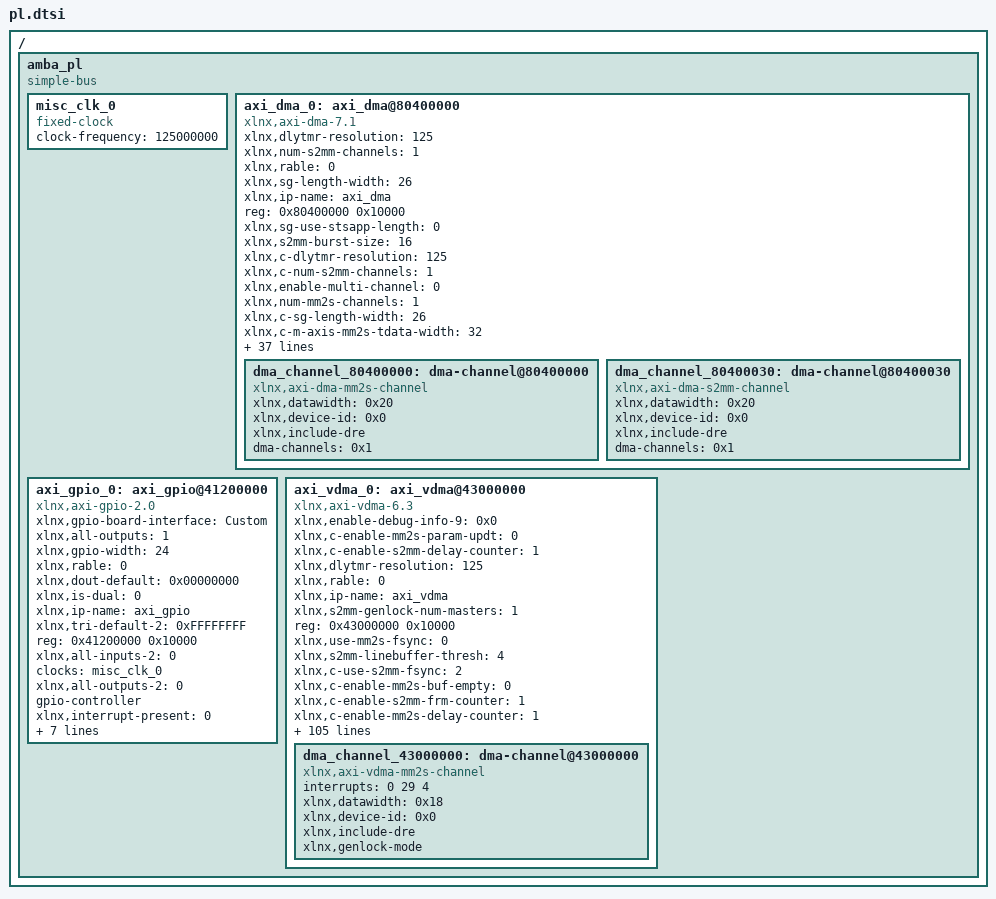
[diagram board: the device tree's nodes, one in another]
/ {
	amba_pl: amba_pl {
		ranges;
		compatible = "simple-bus";
		#address-cells = <1>;
		#size-cells = <1>;
		misc_clk_0: misc_clk_0 {
			compatible = "fixed-clock";
			clock-frequency = <125000000>;
			#clock-cells = <0>;
		};
		axi_dma_0: axi_dma@80400000 {
			xlnx,dlytmr-resolution = <125>;
			xlnx,num-s2mm-channels = <1>;
			xlnx,rable = <0>;
			xlnx,sg-length-width = <26>;
			xlnx,ip-name = "axi_dma";
			reg = <0x80400000 0x10000>;
			xlnx,sg-use-stsapp-length = <0>;
			xlnx,s2mm-burst-size = <16>;
			xlnx,c-dlytmr-resolution = <125>;
			xlnx,c-num-s2mm-channels = <1>;
			xlnx,enable-multi-channel = <0>;
			xlnx,num-mm2s-channels = <1>;
			xlnx,c-sg-length-width = <26>;
			compatible = "xlnx,axi-dma-7.1" , "xlnx,axi-dma-1.00.a";
			xlnx,c-m-axis-mm2s-tdata-width = <32>;
			xlnx,c-sg-use-stsapp-length = <0>;
			xlnx,c-s2mm-burst-size = <16>;
			xlnx,mm2s-burst-size = <16>;
			xlnx,c-enable-multi-channel = <0>;
			xlnx,c-num-mm2s-channels = <1>;
			xlnx,include-s2mm-dre = <1>;
			xlnx,c-mm2s-burst-size = <16>;
			status = "okay";
			xlnx,c-include-s2mm-dre = <1>;
			xlnx,include-mm2s-dre = <1>;
			xlnx,name = "axi_dma_0";
			xlnx,c-include-sg = <0>;
			xlnx,c-m-axi-s2mm-data-width = <32>;
			xlnx,include-s2mm-sf = <1>;
			xlnx,c-include-mm2s-dre = <1>;
			xlnx,include-s2mm = <1>;
			clocks = <&clkc 15>, <&clkc 15>, <&clkc 15>;
			xlnx,addrwidth = <0x20>;
			xlnx,c-m-axi-mm2s-data-width = <32>;
			xlnx,edk-iptype = "PERIPHERAL";
			xlnx,c-include-s2mm-sf = <1>;
			xlnx,include-mm2s-sf = <1>;
			clock-names = "m_axi_mm2s_aclk" , "m_axi_s2mm_aclk" , "s_axi_lite_aclk";
			xlnx,c-include-s2mm = <1>;
			xlnx,c-addr-width = <32>;
			xlnx,c-single-interface = <0>;
			xlnx,include-mm2s = <1>;
			xlnx,c-s-axis-s2mm-tdata-width = <32>;
			xlnx,s2mm-data-width = <0x20>;
			xlnx,c-include-mm2s-sf = <1>;
			xlnx,prmry-is-aclk-async = <0>;
			xlnx,c-include-mm2s = <1>;
			xlnx,increase-throughput = <0>;
			xlnx,micro-dma = <0>;
			xlnx,mm2s-data-width = <0x20>;
			xlnx,c-prmry-is-aclk-async = <0>;
			xlnx,c-sg-include-stscntrl-strm = <0>;
			xlnx,c-increase-throughput = <0>;
			xlnx,c-micro-dma = <0>;
			dma_channel_80400000: dma-channel@80400000 {
				xlnx,datawidth = <0x20>;
				xlnx,device-id = <0x0>;
				compatible = "xlnx,axi-dma-mm2s-channel";
				xlnx,include-dre;
				dma-channels = <0x1>;
			};
			dma_channel_80400030: dma-channel@80400030 {
				xlnx,datawidth = <0x20>;
				xlnx,device-id = <0x0>;
				compatible = "xlnx,axi-dma-s2mm-channel";
				xlnx,include-dre;
				dma-channels = <0x1>;
			};
		};
		axi_gpio_0: axi_gpio@41200000 {
			xlnx,gpio-board-interface = "Custom";
			compatible = "xlnx,axi-gpio-2.0" , "xlnx,xps-gpio-1.00.a";
			xlnx,all-outputs = <1>;
			#gpio-cells = <2>;
			xlnx,gpio-width = <24>;
			xlnx,rable = <0>;
			xlnx,dout-default = <0x00000000>;
			xlnx,is-dual = <0>;
			xlnx,ip-name = "axi_gpio";
			xlnx,tri-default-2 = <0xFFFFFFFF>;
			reg = <0x41200000 0x10000>;
			xlnx,all-inputs-2 = <0>;
			clocks = <&misc_clk_0>;
			xlnx,all-outputs-2 = <0>;
			gpio-controller;
			xlnx,interrupt-present = <0>;
			xlnx,gpio2-board-interface = "Custom";
			xlnx,edk-iptype = "PERIPHERAL";
			xlnx,dout-default-2 = <0x00000000>;
			xlnx,gpio2-width = <32>;
			status = "okay";
			clock-names = "s_axi_aclk";
			xlnx,tri-default = <0xFFFFFFFF>;
			xlnx,name = "axi_gpio_0";
			xlnx,all-inputs = <0>;
		};
		axi_vdma_0: axi_vdma@43000000 {
			xlnx,enable-debug-info-9 = <0x0>;
			xlnx,c-enable-mm2s-param-updt = <0>;
			xlnx,c-enable-s2mm-delay-counter = <1>;
			xlnx,dlytmr-resolution = <125>;
			xlnx,rable = <0>;
			xlnx,ip-name = "axi_vdma";
			xlnx,s2mm-genlock-num-masters = <1>;
			reg = <0x43000000 0x10000>;
			xlnx,use-mm2s-fsync = <0>;
			xlnx,s2mm-linebuffer-thresh = <4>;
			xlnx,c-use-s2mm-fsync = <2>;
			xlnx,c-enable-mm2s-buf-empty = <0>;
			xlnx,c-enable-s2mm-frm-counter = <1>;
			xlnx,c-enable-mm2s-delay-counter = <1>;
			xlnx,c-dlytmr-resolution = <125>;
			xlnx,c-enable-s2mm-buf-full = <0>;
			xlnx,dynamic-resolution = <1>;
			interrupt-names = "mm2s_introut";
			xlnx,s2mm-sof-enable = <0x1>;
			xlnx,mm2s-genlock-num-masters = <1>;
			xlnx,c-s2mm-genlock-num-masters = <1>;
			xlnx,c-enable-s2mm-fsync-out = <0>;
			xlnx,mm2s-linebuffer-thresh = <4>;
			xlnx,c-use-mm2s-fsync = <0>;
			xlnx,c-s2mm-linebuffer-thresh = <4>;
			xlnx,c-enable-mm2s-frm-counter = <1>;
			compatible = "xlnx,axi-vdma-6.3" , "xlnx,axi-vdma-1.00.a";
			xlnx,c-m-axis-mm2s-tdata-width = <24>;
			xlnx,c-enable-all = <0>;
			interrupt-parent = <&intc>;
			xlnx,s2mm-max-burst-length = <8>;
			xlnx,c-dynamic-resolution = <1>;
			xlnx,c-enable-s2mm-rst-out = <0>;
			xlnx,mm2s-sof-enable = <1>;
			xlnx,include-s2mm-dre = <0x0>;
			xlnx,c-s2mm-sof-enable = <1>;
			xlnx,c-enable-mm2s-fsync-out = <0>;
			xlnx,c-mm2s-genlock-num-masters = <1>;
			xlnx,c-mm2s-linebuffer-thresh = <4>;
			xlnx,c-enable-tstvec = <0>;
			xlnx,mm2s-max-burst-length = <8>;
			xlnx,c-s2mm-max-burst-length = <8>;
			status = "okay";
			xlnx,c-enable-mm2s-rst-out = <0>;
			xlnx,include-mm2s-dre = <0x1>;
			xlnx,c-include-s2mm-dre = <0>;
			xlnx,c-mm2s-sof-enable = <1>;
			xlnx,name = "axi_vdma_0";
			xlnx,c-enable-s2mm-frmstr-reg = <0>;
			interrupts = < 0 29 4 >;
			xlnx,c-include-sg = <0>;
			xlnx,flush-on-fsync = <0x1>;
			xlnx,c-m-axi-s2mm-data-width = <64>;
			xlnx,c-enable-s2mm-sts-reg = <0>;
			xlnx,include-s2mm-sf = <1>;
			xlnx,c-mm2s-max-burst-length = <8>;
			xlnx,s2mm-linebuffer-depth = <0x200>;
			xlnx,include-s2mm = <0x0>;
			xlnx,c-include-mm2s-dre = <1>;
			clocks = <&misc_clk_0>, <&misc_clk_0>, <&misc_clk_0>;
			xlnx,c-enable-mm2s-frmstr-reg = <0>;
			xlnx,enable-debug-info-10 = <0>;
			xlnx,addrwidth = <0x20>;
			xlnx,enable-debug-info-11 = <0>;
			xlnx,enable-debug-info-12 = <0>;
			xlnx,edk-iptype = "PERIPHERAL";
			xlnx,c-flush-on-fsync = <1>;
			xlnx,c-m-axi-mm2s-data-width = <64>;
			xlnx,use-fsync = <1>;
			xlnx,s2mm-genlock-repeat-en = <1>;
			xlnx,enable-vert-flip = <0x0>;
			xlnx,enable-debug-info-13 = <0x0>;
			xlnx,include-mm2s-sf = <0>;
			xlnx,include-internal-genlock = <0x1>;
			xlnx,enable-debug-info-14 = <0x1>;
			xlnx,c-include-s2mm-sf = <1>;
			clock-names = "m_axi_mm2s_aclk" , "m_axis_mm2s_aclk" , "s_axi_lite_aclk";
			xlnx,enable-debug-info-15 = <0x1>;
			xlnx,mm2s-linebuffer-depth = <0x200>;
			xlnx,include-mm2s = <0x1>;
			xlnx,c-single-interface = <0>;
			xlnx,c-s2mm-linebuffer-depth = <512>;
			xlnx,c-addr-width = <32>;
			xlnx,c-include-s2mm = <0>;
			xlnx,s2mm-genlock-mode = <0x0>;
			xlnx,c-s-axis-s2mm-tdata-width = <32>;
			xlnx,flush-fsync = <0x1>;
			xlnx,select-xpm = <0>;
			xlnx,s2mm-data-width = <0x40>;
			xlnx,num-fstores = <0x1>;
			xlnx,enable-vidparam-reads = <0x1>;
			xlnx,mm2s-genlock-repeat-en = <0>;
			xlnx,c-use-fsync = <1>;
			xlnx,c-s2mm-genlock-repeat-en = <1>;
			xlnx,c-enable-vert-flip = <0>;
			xlnx,prmry-is-aclk-async = <0>;
			xlnx,c-include-internal-genlock = <1>;
			xlnx,c-include-mm2s-sf = <0>;
			xlnx,s2mm-tdata-width = <0x20>;
			xlnx,enable-vidprmtr-reads = <1>;
			xlnx,c-include-mm2s = <1>;
			xlnx,c-mm2s-linebuffer-depth = <512>;
			xlnx,mm2s-genlock-mode = <0x3>;
			xlnx,enable-debug-info-0 = <0>;
			xlnx,enable-debug-all = <0x0>;
			xlnx,c-s2mm-genlock-mode = <0>;
			xlnx,enable-debug-info-1 = <0x0>;
			xlnx,mm2s-data-width = <0x40>;
			xlnx,enable-debug-info-2 = <0>;
			xlnx,c-enable-s2mm-param-updt = <0>;
			xlnx,c-num-fstores = <1>;
			xlnx,enable-debug-info-3 = <0>;
			xlnx,enable-debug-info-4 = <0>;
			xlnx,c-mm2s-genlock-repeat-en = <0>;
			xlnx,enable-debug-info-5 = <0x0>;
			xlnx,c-prmry-is-aclk-async = <0>;
			xlnx,mm2s-tdata-width = <0x18>;
			xlnx,enable-debug-info-6 = <0x1>;
			xlnx,enable-debug-info-7 = <0x1>;
			xlnx,c-enable-vidprmtr-reads = <1>;
			xlnx,use-s2mm-fsync = <2>;
			xlnx,enable-debug-info-8 = <0>;
			xlnx,c-mm2s-genlock-mode = <3>;
			dma_channel_43000000: dma-channel@43000000 {
				interrupts = < 0 29 4 >;
				xlnx,datawidth = <0x18>;
				xlnx,device-id = <0x0>;
				compatible = "xlnx,axi-vdma-mm2s-channel";
				xlnx,include-dre;
				xlnx,genlock-mode;
			};
		};
	};
};
